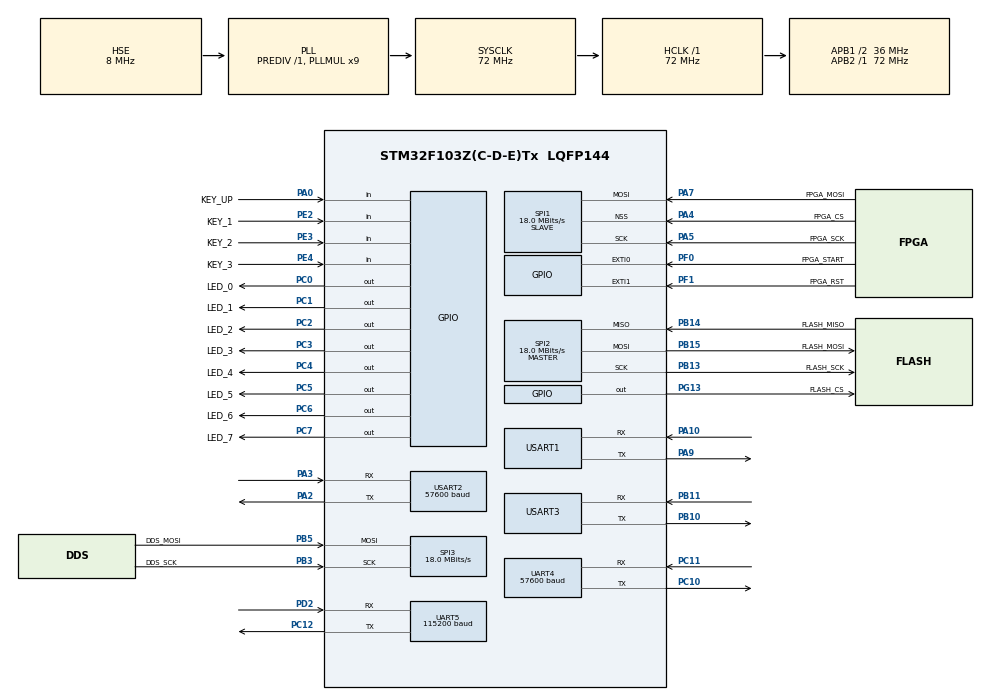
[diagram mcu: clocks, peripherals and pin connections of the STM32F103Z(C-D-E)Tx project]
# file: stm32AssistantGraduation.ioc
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FREERTOS.INCLUDE_pcTaskGetTaskName=1
FREERTOS.INCLUDE_xTaskGetCurrentTaskHandle=1
FREERTOS.Queues01=mainQueue,50,void *,0,Dynamic,NULL,NULL;coreQueue,20,uint8_t,0,Dynamic,NULL,NULL;modemQueue,16,void *,0,Dynamic,NULL,NULL
FREERTOS.Tasks01=mainTask,0,1024,app_main,As weak,NULL,Dynamic,NULL,NULL;coreTask,3,512,app_core,As weak,NULL,Dynamic,NULL,NULL;modemTask,-3,512,app_modem,As weak,NULL,Dynamic,NULL,NULL
FREERTOS.Timers01=timer1,timer1_cb,osTimerPeriodic,As weak,NULL,Dynamic,NULL
FREERTOS.configTIMER_TASK_PRIORITY=5
FREERTOS.configTOTAL_HEAP_SIZE=49152
FREERTOS.configUSE_TIMERS=1
IWDG.Prescaler=IWDG_PRESCALER_32
IWDG.Reload=2499
Mcu.Family=STM32F1
Mcu.Name=STM32F103Z(C-D-E)Tx
Mcu.Package=LQFP144
NVIC.EXTI0_IRQn=true\:5\:0\:false\:false\:true\:true\:true\:true
NVIC.EXTI1_IRQn=true\:5\:0\:false\:false\:true\:true\:true\:true
NVIC.PriorityGroup=NVIC_PRIORITYGROUP_4
NVIC.SPI1_IRQn=true\:5\:0\:false\:false\:true\:true\:true\:true
NVIC.SPI3_IRQn=true\:5\:0\:false\:false\:true\:true\:true\:true
NVIC.UART4_IRQn=true\:5\:0\:false\:false\:true\:true\:true\:true
NVIC.UART5_IRQn=true\:5\:0\:false\:false\:true\:true\:true\:true
NVIC.USART1_IRQn=true\:5\:0\:false\:false\:true\:true\:true\:true
NVIC.USART2_IRQn=true\:5\:0\:false\:false\:true\:true\:true\:true
NVIC.USART3_IRQn=true\:5\:0\:false\:false\:true\:true\:true\:true
OSC_IN.Mode=HSE-External-Oscillator
OSC_IN.Signal=RCC_OSC_IN
OSC_OUT.Mode=HSE-External-Oscillator
OSC_OUT.Signal=RCC_OSC_OUT
PA0-WKUP.GPIO_Label=KEY_UP
PA0-WKUP.GPIO_PuPd=GPIO_PULLDOWN
PA0-WKUP.Signal=GPIO_Input
PA10.Mode=Asynchronous
PA10.Signal=USART1_RX
PA2.Mode=Asynchronous
PA2.Signal=USART2_TX
PA3.Mode=Asynchronous
PA3.Signal=USART2_RX
PA4.GPIO_Label=FPGA_CS
PA4.Mode=NSS_Signal_Hard_Input
PA4.Signal=SPI1_NSS
PA5.GPIO_Label=FPGA_SCK
PA5.Mode=RX_Only_Simplex_Unidirect_Slave
PA5.Signal=SPI1_SCK
PA7.GPIO_Label=FPGA_MOSI
PA7.Mode=RX_Only_Simplex_Unidirect_Slave
PA7.Signal=SPI1_MOSI
PA9.Mode=Asynchronous
PA9.Signal=USART1_TX
PB10.Mode=Asynchronous
PB10.Signal=USART3_TX
PB11.Mode=Asynchronous
PB11.Signal=USART3_RX
PB13.GPIO_Label=FLASH_SCK
PB13.Mode=Full_Duplex_Master
PB13.Signal=SPI2_SCK
PB14.GPIO_Label=FLASH_MISO
PB14.Mode=Full_Duplex_Master
PB14.Signal=SPI2_MISO
PB15.GPIO_Label=FLASH_MOSI
PB15.Mode=Full_Duplex_Master
PB15.Signal=SPI2_MOSI
PB3.GPIO_Label=DDS_SCK
PB3.Mode=RX_Only_Simplex_Unidirect_Slave
PB3.Signal=SPI3_SCK
PB5.GPIO_Label=DDS_MOSI
PB5.Mode=RX_Only_Simplex_Unidirect_Slave
PB5.Signal=SPI3_MOSI
PC0.GPIO_Label=LED_0
PC0.GPIO_ModeDefaultOutputPP=GPIO_MODE_OUTPUT_PP
PC0.GPIO_PuPd=GPIO_NOPULL
PC0.GPIO_Speed=GPIO_SPEED_FREQ_HIGH
PC0.PinState=GPIO_PIN_SET
PC0.Signal=GPIO_Output
PC1.GPIO_Label=LED_1
PC1.GPIO_ModeDefaultOutputPP=GPIO_MODE_OUTPUT_PP
PC1.GPIO_PuPd=GPIO_NOPULL
PC1.GPIO_Speed=GPIO_SPEED_FREQ_HIGH
PC1.PinState=GPIO_PIN_SET
PC1.Signal=GPIO_Output
PC10.Mode=Asynchronous
PC10.Signal=UART4_TX
PC11.Mode=Asynchronous
PC11.Signal=UART4_RX
PC12.Mode=Asynchronous
PC12.Signal=UART5_TX
PC2.GPIO_Label=LED_2
PC2.GPIO_ModeDefaultOutputPP=GPIO_MODE_OUTPUT_PP
PC2.GPIO_PuPd=GPIO_NOPULL
PC2.GPIO_Speed=GPIO_SPEED_FREQ_HIGH
PC2.PinState=GPIO_PIN_SET
PC2.Signal=GPIO_Output
PC3.GPIO_Label=LED_3
PC3.GPIO_ModeDefaultOutputPP=GPIO_MODE_OUTPUT_PP
PC3.GPIO_PuPd=GPIO_NOPULL
PC3.GPIO_Speed=GPIO_SPEED_FREQ_HIGH
PC3.PinState=GPIO_PIN_SET
PC3.Signal=GPIO_Output
PC4.GPIO_Label=LED_4
PC4.GPIO_ModeDefaultOutputPP=GPIO_MODE_OUTPUT_PP
PC4.GPIO_PuPd=GPIO_NOPULL
PC4.GPIO_Speed=GPIO_SPEED_FREQ_HIGH
PC4.PinState=GPIO_PIN_SET
PC4.Signal=GPIO_Output
PC5.GPIO_Label=LED_5
PC5.GPIO_ModeDefaultOutputPP=GPIO_MODE_OUTPUT_PP
PC5.GPIO_PuPd=GPIO_NOPULL
PC5.GPIO_Speed=GPIO_SPEED_FREQ_HIGH
PC5.PinState=GPIO_PIN_SET
PC5.Signal=GPIO_Output
PC6.GPIO_Label=LED_6
PC6.GPIO_ModeDefaultOutputPP=GPIO_MODE_OUTPUT_PP
PC6.GPIO_PuPd=GPIO_NOPULL
PC6.GPIO_Speed=GPIO_SPEED_FREQ_HIGH
PC6.PinState=GPIO_PIN_SET
PC6.Signal=GPIO_Output
PC7.GPIO_Label=LED_7
PC7.GPIO_ModeDefaultOutputPP=GPIO_MODE_OUTPUT_PP
PC7.GPIO_PuPd=GPIO_NOPULL
PC7.GPIO_Speed=GPIO_SPEED_FREQ_HIGH
PC7.PinState=GPIO_PIN_SET
PC7.Signal=GPIO_Output
PD2.Mode=Asynchronous
PD2.Signal=UART5_RX
PE2.GPIO_Label=KEY_1
PE2.GPIO_Mode=GPIO_MODE_INPUT
PE2.GPIO_PuPd=GPIO_PULLUP
PE2.Signal=GPIO_Input
PE3.GPIO_Label=KEY_2
PE3.GPIO_Mode=GPIO_MODE_INPUT
PE3.GPIO_PuPd=GPIO_PULLUP
PE3.Signal=GPIO_Input
PE4.GPIO_Label=KEY_3
PE4.GPIO_Mode=GPIO_MODE_INPUT
PE4.GPIO_PuPd=GPIO_PULLUP
PE4.Signal=GPIO_Input
PF0.GPIO_Label=FPGA_START
PF0.GPIO_ModeDefaultEXTI=GPIO_MODE_IT_RISING_FALLING
PF0.Signal=GPXTI0
PF1.GPIO_Label=FPGA_RST
PF1.GPIO_ModeDefaultEXTI=GPIO_MODE_IT_RISING_FALLING
PF1.Signal=GPXTI1
PG13.GPIO_Label=FLASH_CS
PG13.GPIO_ModeDefaultOutputPP=GPIO_MODE_OUTPUT_PP
PG13.GPIO_PuPd=GPIO_NOPULL
PG13.GPIO_Speed=GPIO_SPEED_FREQ_HIGH
PG13.PinState=GPIO_PIN_SET
PG13.Signal=GPIO_Output
ProjectManager.HeapSize=0x200
ProjectManager.StackSize=0x400
ProjectManager.TargetToolchain=MDK-ARM V5
RCC.AHBFreq_Value=72000000
RCC.APB1CLKDivider=RCC_HCLK_DIV2
RCC.APB1Freq_Value=36000000
RCC.APB1TimFreq_Value=72000000
RCC.APB2Freq_Value=72000000
RCC.APB2TimFreq_Value=72000000
RCC.HCLKFreq_Value=72000000
RCC.PLLMUL=RCC_PLL_MUL9
RCC.PLLSourceVirtual=RCC_PLLSOURCE_HSE
RCC.SYSCLKFreq_VALUE=72000000
RCC.SYSCLKSource=RCC_SYSCLKSOURCE_PLLCLK
RCC.USBFreq_Value=72000000
SPI1.BaudRatePrescaler=SPI_BAUDRATEPRESCALER_4
SPI1.CalculateBaudRate=18.0 MBits/s
SPI1.Direction=SPI_DIRECTION_2LINES_RXONLY
SPI1.Mode=SPI_MODE_SLAVE
SPI1.VirtualNSS=VM_NSSHARD
SPI1.VirtualType=VM_SLAVE
SPI2.CalculateBaudRate=18.0 MBits/s
SPI2.Direction=SPI_DIRECTION_2LINES
SPI2.Mode=SPI_MODE_MASTER
SPI2.VirtualType=VM_MASTER
SPI3.CLKPolarity=SPI_POLARITY_HIGH
SPI3.CalculateBaudRate=18.0 MBits/s
SPI3.DataSize=SPI_DATASIZE_16BIT
SPI3.Direction=SPI_DIRECTION_2LINES_RXONLY
SPI3.Mode=SPI_MODE_SLAVE
SPI3.VirtualType=VM_SLAVE
UART4.BaudRate=57600
UART4.VirtualMode=Asynchronous
UART5.BaudRate=115200
UART5.VirtualMode=Asynchronous
USART1.VirtualMode=VM_ASYNC
USART2.BaudRate=57600
USART2.VirtualMode=VM_ASYNC
USART3.VirtualMode=VM_ASYNC
VP_FREERTOS_VS_CMSIS_V1.Mode=CMSIS_V1
VP_IWDG_VS_IWDG.Mode=IWDG_Activate
VP_SYS_VS_ND.Mode=No_Debug
board=custom

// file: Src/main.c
/* USER CODE BEGIN Header */
/**
  ******************************************************************************
  * @file           : main.c
  * @brief          : Main program body
  ******************************************************************************
  * @attention
  *
  * <h2><center>&copy; Copyright (c) 2019 STMicroelectronics.
  * All rights reserved.</center></h2>
  *
  * This software component is licensed by ST under Ultimate Liberty license
  * SLA0044, the "License"; You may not use this file except in compliance with
  * the License. You may obtain a copy of the License at:
  *                             www.st.com/SLA0044
  *
  ******************************************************************************
  */
/* USER CODE END Header */

#include "main.h"
#include "cmsis_os.h"

/* USER CODE BEGIN Includes */
#include "types.h"
#include "app_main.h"
#include "app_core.h"
#include "app_modem.h"
#include "timer.h"
/* USER CODE END Includes */

IWDG_HandleTypeDef hiwdg;

SPI_HandleTypeDef hspi1;
SPI_HandleTypeDef hspi2;
SPI_HandleTypeDef hspi3;

UART_HandleTypeDef huart4;
UART_HandleTypeDef huart5;
UART_HandleTypeDef huart1;
UART_HandleTypeDef huart2;
UART_HandleTypeDef huart3;

osThreadId mainTaskHandle;
osThreadId coreTaskHandle;
osThreadId modemTaskHandle;
osMessageQId mainQueueHandle;
osMessageQId coreQueueHandle;
osMessageQId modemQueueHandle;
osTimerId timer1Handle;

void SystemClock_Config(void);
static void MX_GPIO_Init(void);
static void MX_SPI2_Init(void);
static void MX_USART1_UART_Init(void);
static void MX_SPI1_Init(void);
static void MX_SPI3_Init(void);
static void MX_UART4_Init(void);
static void MX_UART5_Init(void);
static void MX_USART2_UART_Init(void);
static void MX_USART3_UART_Init(void);
static void MX_IWDG_Init(void);
void app_main(void const * argument);
void app_core(void const * argument);
void app_modem(void const * argument);
void timer1_cb(void const * argument);

int main(void)
{

  /* MCU Configuration--------------------------------------------------------*/

  /* Reset of all peripherals, Initializes the Flash interface and the Systick. */
  HAL_Init();

  /* Configure the system clock */
  SystemClock_Config();

  /* Initialize all configured peripherals */
  MX_GPIO_Init();
  MX_SPI2_Init();
  MX_USART1_UART_Init();
  MX_SPI1_Init();
  MX_SPI3_Init();
  MX_UART4_Init();
  MX_UART5_Init();
  MX_USART2_UART_Init();
  MX_USART3_UART_Init();
  MX_IWDG_Init();
  /* USER CODE BEGIN 2 */
  stm32_init();
  /* USER CODE END 2 */

  /* Create the timer(s) */
  /* definition and creation of timer1 */
  osTimerDef(timer1, timer1_cb);
  timer1Handle = osTimerCreate(osTimer(timer1), osTimerPeriodic, NULL);

  /* USER CODE BEGIN RTOS_TIMERS */
  /* start timers, add new ones, ... */
  osTimerStart(timer1Handle, 1);
  /* USER CODE END RTOS_TIMERS */

  /* Create the queue(s) */
  /* definition and creation of mainQueue */
  osMessageQDef(mainQueue, 50, void *);
  mainQueueHandle = osMessageCreate(osMessageQ(mainQueue), NULL);

  /* definition and creation of coreQueue */
  osMessageQDef(coreQueue, 20, uint8_t);
  coreQueueHandle = osMessageCreate(osMessageQ(coreQueue), NULL);

  /* definition and creation of modemQueue */
  osMessageQDef(modemQueue, 16, void *);
  modemQueueHandle = osMessageCreate(osMessageQ(modemQueue), NULL);

  /* Create the thread(s) */
  /* definition and creation of mainTask */
  osThreadDef(mainTask, app_main, osPriorityNormal, 0, 1024);
  mainTaskHandle = osThreadCreate(osThread(mainTask), NULL);

  /* definition and creation of coreTask */
  osThreadDef(coreTask, app_core, osPriorityRealtime, 0, 512);
  coreTaskHandle = osThreadCreate(osThread(coreTask), NULL);

  /* definition and creation of modemTask */
  osThreadDef(modemTask, app_modem, osPriorityIdle, 0, 512);
  modemTaskHandle = osThreadCreate(osThread(modemTask), NULL);

  /* Start scheduler */
  osKernelStart();

  /* We should never get here as control is now taken by the scheduler */

  /* Infinite loop */
  while (1)
  {

  }
}

void SystemClock_Config(void)
{
  RCC_OscInitTypeDef RCC_OscInitStruct = {0};
  RCC_ClkInitTypeDef RCC_ClkInitStruct = {0};

  /** Initializes the CPU, AHB and APB busses clocks
  */
  RCC_OscInitStruct.OscillatorType = RCC_OSCILLATORTYPE_LSI|RCC_OSCILLATORTYPE_HSE;
  RCC_OscInitStruct.HSEState = RCC_HSE_ON;
  RCC_OscInitStruct.HSEPredivValue = RCC_HSE_PREDIV_DIV1;
  RCC_OscInitStruct.HSIState = RCC_HSI_ON;
  RCC_OscInitStruct.LSIState = RCC_LSI_ON;
  RCC_OscInitStruct.PLL.PLLState = RCC_PLL_ON;
  RCC_OscInitStruct.PLL.PLLSource = RCC_PLLSOURCE_HSE;
  RCC_OscInitStruct.PLL.PLLMUL = RCC_PLL_MUL9;
  if (HAL_RCC_OscConfig(&RCC_OscInitStruct) != HAL_OK)
  {
    Error_Handler();
  }
  /** Initializes the CPU, AHB and APB busses clocks
  */
  RCC_ClkInitStruct.ClockType = RCC_CLOCKTYPE_HCLK|RCC_CLOCKTYPE_SYSCLK
                              |RCC_CLOCKTYPE_PCLK1|RCC_CLOCKTYPE_PCLK2;
  RCC_ClkInitStruct.SYSCLKSource = RCC_SYSCLKSOURCE_PLLCLK;
  RCC_ClkInitStruct.AHBCLKDivider = RCC_SYSCLK_DIV1;
  RCC_ClkInitStruct.APB1CLKDivider = RCC_HCLK_DIV2;
  RCC_ClkInitStruct.APB2CLKDivider = RCC_HCLK_DIV1;

  if (HAL_RCC_ClockConfig(&RCC_ClkInitStruct, FLASH_LATENCY_2) != HAL_OK)
  {
    Error_Handler();
  }
}

static void MX_IWDG_Init(void)
{

  hiwdg.Instance = IWDG;
  hiwdg.Init.Prescaler = IWDG_PRESCALER_32;
  hiwdg.Init.Reload = 2499;
  if (HAL_IWDG_Init(&hiwdg) != HAL_OK)
  {
    Error_Handler();
  }

}

static void MX_SPI1_Init(void)
{

  /* SPI1 parameter configuration*/
  hspi1.Instance = SPI1;
  hspi1.Init.Mode = SPI_MODE_SLAVE;
  hspi1.Init.Direction = SPI_DIRECTION_2LINES_RXONLY;
  hspi1.Init.DataSize = SPI_DATASIZE_8BIT;
  hspi1.Init.CLKPolarity = SPI_POLARITY_LOW;
  hspi1.Init.CLKPhase = SPI_PHASE_1EDGE;
  hspi1.Init.NSS = SPI_NSS_HARD_INPUT;
  hspi1.Init.BaudRatePrescaler = SPI_BAUDRATEPRESCALER_4;
  hspi1.Init.FirstBit = SPI_FIRSTBIT_MSB;
  hspi1.Init.TIMode = SPI_TIMODE_DISABLE;
  hspi1.Init.CRCCalculation = SPI_CRCCALCULATION_DISABLE;
  hspi1.Init.CRCPolynomial = 10;
  if (HAL_SPI_Init(&hspi1) != HAL_OK)
  {
    Error_Handler();
  }

}

static void MX_SPI2_Init(void)
{

  /* SPI2 parameter configuration*/
  hspi2.Instance = SPI2;
  hspi2.Init.Mode = SPI_MODE_MASTER;
  hspi2.Init.Direction = SPI_DIRECTION_2LINES;
  hspi2.Init.DataSize = SPI_DATASIZE_8BIT;
  hspi2.Init.CLKPolarity = SPI_POLARITY_LOW;
  hspi2.Init.CLKPhase = SPI_PHASE_1EDGE;
  hspi2.Init.NSS = SPI_NSS_SOFT;
  hspi2.Init.BaudRatePrescaler = SPI_BAUDRATEPRESCALER_2;
  hspi2.Init.FirstBit = SPI_FIRSTBIT_MSB;
  hspi2.Init.TIMode = SPI_TIMODE_DISABLE;
  hspi2.Init.CRCCalculation = SPI_CRCCALCULATION_DISABLE;
  hspi2.Init.CRCPolynomial = 10;
  if (HAL_SPI_Init(&hspi2) != HAL_OK)
  {
    Error_Handler();
  }

}

static void MX_SPI3_Init(void)
{

  /* SPI3 parameter configuration*/
  hspi3.Instance = SPI3;
  hspi3.Init.Mode = SPI_MODE_SLAVE;
  hspi3.Init.Direction = SPI_DIRECTION_2LINES_RXONLY;
  hspi3.Init.DataSize = SPI_DATASIZE_16BIT;
  hspi3.Init.CLKPolarity = SPI_POLARITY_HIGH;
  hspi3.Init.CLKPhase = SPI_PHASE_1EDGE;
  hspi3.Init.NSS = SPI_NSS_SOFT;
  hspi3.Init.BaudRatePrescaler = SPI_BAUDRATEPRESCALER_2;
  hspi3.Init.FirstBit = SPI_FIRSTBIT_MSB;
  hspi3.Init.TIMode = SPI_TIMODE_DISABLE;
  hspi3.Init.CRCCalculation = SPI_CRCCALCULATION_DISABLE;
  hspi3.Init.CRCPolynomial = 10;
  if (HAL_SPI_Init(&hspi3) != HAL_OK)
  {
    Error_Handler();
  }

}

static void MX_UART4_Init(void)
{

  huart4.Instance = UART4;
  huart4.Init.BaudRate = 57600;
  huart4.Init.WordLength = UART_WORDLENGTH_8B;
  huart4.Init.StopBits = UART_STOPBITS_1;
  huart4.Init.Parity = UART_PARITY_NONE;
  huart4.Init.Mode = UART_MODE_TX_RX;
  huart4.Init.HwFlowCtl = UART_HWCONTROL_NONE;
  huart4.Init.OverSampling = UART_OVERSAMPLING_16;
  if (HAL_UART_Init(&huart4) != HAL_OK)
  {
    Error_Handler();
  }

}

static void MX_UART5_Init(void)
{

  huart5.Instance = UART5;
  huart5.Init.BaudRate = 115200;
  huart5.Init.WordLength = UART_WORDLENGTH_8B;
  huart5.Init.StopBits = UART_STOPBITS_1;
  huart5.Init.Parity = UART_PARITY_NONE;
  huart5.Init.Mode = UART_MODE_TX_RX;
  huart5.Init.HwFlowCtl = UART_HWCONTROL_NONE;
  huart5.Init.OverSampling = UART_OVERSAMPLING_16;
  if (HAL_UART_Init(&huart5) != HAL_OK)
  {
    Error_Handler();
  }

}

static void MX_USART1_UART_Init(void)
{

  huart1.Instance = USART1;
  huart1.Init.BaudRate = 115200;
  huart1.Init.WordLength = UART_WORDLENGTH_8B;
  huart1.Init.StopBits = UART_STOPBITS_1;
  huart1.Init.Parity = UART_PARITY_NONE;
  huart1.Init.Mode = UART_MODE_TX_RX;
  huart1.Init.HwFlowCtl = UART_HWCONTROL_NONE;
  huart1.Init.OverSampling = UART_OVERSAMPLING_16;
  if (HAL_UART_Init(&huart1) != HAL_OK)
  {
    Error_Handler();
  }

}

static void MX_USART2_UART_Init(void)
{

  huart2.Instance = USART2;
  huart2.Init.BaudRate = 57600;
  huart2.Init.WordLength = UART_WORDLENGTH_8B;
  huart2.Init.StopBits = UART_STOPBITS_1;
  huart2.Init.Parity = UART_PARITY_NONE;
  huart2.Init.Mode = UART_MODE_TX_RX;
  huart2.Init.HwFlowCtl = UART_HWCONTROL_NONE;
  huart2.Init.OverSampling = UART_OVERSAMPLING_16;
  if (HAL_UART_Init(&huart2) != HAL_OK)
  {
    Error_Handler();
  }

}

static void MX_USART3_UART_Init(void)
{

  huart3.Instance = USART3;
  huart3.Init.BaudRate = 115200;
  huart3.Init.WordLength = UART_WORDLENGTH_8B;
  huart3.Init.StopBits = UART_STOPBITS_1;
  huart3.Init.Parity = UART_PARITY_NONE;
  huart3.Init.Mode = UART_MODE_TX_RX;
  huart3.Init.HwFlowCtl = UART_HWCONTROL_NONE;
  huart3.Init.OverSampling = UART_OVERSAMPLING_16;
  if (HAL_UART_Init(&huart3) != HAL_OK)
  {
    Error_Handler();
  }

}

static void MX_GPIO_Init(void)
{
  GPIO_InitTypeDef GPIO_InitStruct = {0};

  /* GPIO Ports Clock Enable */
  __HAL_RCC_GPIOE_CLK_ENABLE();
  __HAL_RCC_GPIOF_CLK_ENABLE();
  __HAL_RCC_GPIOC_CLK_ENABLE();
  __HAL_RCC_GPIOA_CLK_ENABLE();
  __HAL_RCC_GPIOB_CLK_ENABLE();
  __HAL_RCC_GPIOD_CLK_ENABLE();
  __HAL_RCC_GPIOG_CLK_ENABLE();

  /*Configure GPIO pin Output Level */
  HAL_GPIO_WritePin(GPIOC, LED_0_Pin|LED_1_Pin|LED_2_Pin|LED_3_Pin
                          |LED_4_Pin|LED_5_Pin|LED_6_Pin|LED_7_Pin, GPIO_PIN_SET);

  /*Configure GPIO pin Output Level */
  HAL_GPIO_WritePin(FLASH_CS_GPIO_Port, FLASH_CS_Pin, GPIO_PIN_SET);

  /*Configure GPIO pins : KEY_1_Pin KEY_2_Pin KEY_3_Pin */
  GPIO_InitStruct.Pin = KEY_1_Pin|KEY_2_Pin|KEY_3_Pin;
  GPIO_InitStruct.Mode = GPIO_MODE_INPUT;
  GPIO_InitStruct.Pull = GPIO_PULLUP;
  HAL_GPIO_Init(GPIOE, &GPIO_InitStruct);

  /*Configure GPIO pins : FPGA_START_Pin FPGA_RST_Pin */
  GPIO_InitStruct.Pin = FPGA_START_Pin|FPGA_RST_Pin;
  GPIO_InitStruct.Mode = GPIO_MODE_IT_RISING_FALLING;
  GPIO_InitStruct.Pull = GPIO_NOPULL;
  HAL_GPIO_Init(GPIOF, &GPIO_InitStruct);

  /*Configure GPIO pins : LED_0_Pin LED_1_Pin LED_2_Pin LED_3_Pin
                           LED_4_Pin LED_5_Pin LED_6_Pin LED_7_Pin */
  GPIO_InitStruct.Pin = LED_0_Pin|LED_1_Pin|LED_2_Pin|LED_3_Pin
                          |LED_4_Pin|LED_5_Pin|LED_6_Pin|LED_7_Pin;
  GPIO_InitStruct.Mode = GPIO_MODE_OUTPUT_PP;
  GPIO_InitStruct.Pull = GPIO_NOPULL;
  GPIO_InitStruct.Speed = GPIO_SPEED_FREQ_HIGH;
  HAL_GPIO_Init(GPIOC, &GPIO_InitStruct);

  /*Configure GPIO pin : KEY_UP_Pin */
  GPIO_InitStruct.Pin = KEY_UP_Pin;
  GPIO_InitStruct.Mode = GPIO_MODE_INPUT;
  GPIO_InitStruct.Pull = GPIO_PULLDOWN;
  HAL_GPIO_Init(KEY_UP_GPIO_Port, &GPIO_InitStruct);

  /*Configure GPIO pin : FLASH_CS_Pin */
  GPIO_InitStruct.Pin = FLASH_CS_Pin;
  GPIO_InitStruct.Mode = GPIO_MODE_OUTPUT_PP;
  GPIO_InitStruct.Pull = GPIO_NOPULL;
  GPIO_InitStruct.Speed = GPIO_SPEED_FREQ_HIGH;
  HAL_GPIO_Init(FLASH_CS_GPIO_Port, &GPIO_InitStruct);

  /* EXTI interrupt init*/
  HAL_NVIC_SetPriority(EXTI0_IRQn, 5, 0);
  HAL_NVIC_EnableIRQ(EXTI0_IRQn);

  HAL_NVIC_SetPriority(EXTI1_IRQn, 5, 0);
  HAL_NVIC_EnableIRQ(EXTI1_IRQn);

}

__weak void app_main(void const * argument)
{

  for(;;)
  {
    osDelay(1);
  }
}

__weak void app_core(void const * argument)
{
  for(;;)
  {
    osDelay(1);
  }
}

__weak void app_modem(void const * argument)
{
  for(;;)
  {
    osDelay(1);
  }
}

/* timer1_cb function */
__weak void timer1_cb(void const * argument)
{
}

void Error_Handler(void)
{
}

/************************ (C) COPYRIGHT STMicroelectronics *****END OF FILE****/
